CM_ "IMPORT _honda_common.dbc";
CM_ "IMPORT _bosch_2018.dbc";
CM_ "IMPORT _bosch_adas_2018.dbc";
CM_ "IMPORT _bosch_standstill.dbc";
CM_ "IMPORT _steering_sensors_b.dbc";

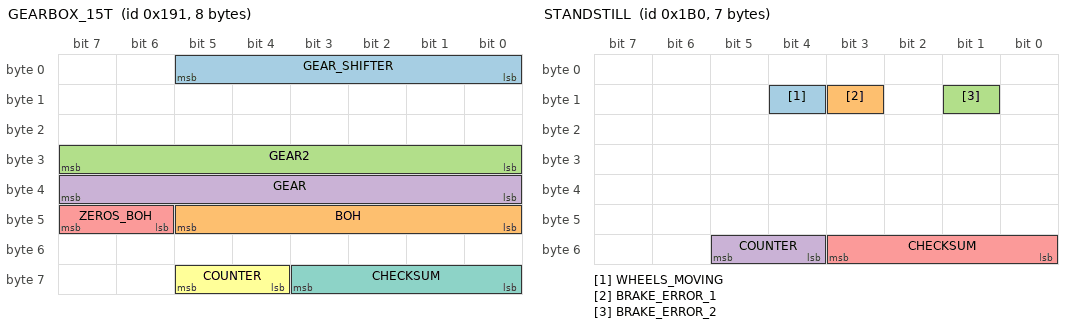
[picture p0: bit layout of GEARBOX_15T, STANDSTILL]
BO_ 401 GEARBOX_15T: 8 PCM
 SG_ GEAR_SHIFTER : 5|6@0+ (1,0) [0|63] "" EON
 SG_ BOH : 45|6@0+ (1,0) [0|63] "" XXX
 SG_ GEAR2 : 31|8@0+ (1,0) [0|1] "" XXX
 SG_ GEAR : 39|8@0+ (1,0) [0|255] "" XXX
 SG_ ZEROS_BOH : 47|2@0+ (1,0) [0|3] "" XXX
 SG_ COUNTER : 61|2@0+ (1,0) [0|3] "" EON
 SG_ CHECKSUM : 59|4@0+ (1,0) [0|15] "" EON

BO_ 432 STANDSTILL: 7 VSA
 SG_ WHEELS_MOVING : 12|1@0+ (1,0) [0|1] "" EON
 SG_ BRAKE_ERROR_1 : 11|1@0+ (1,0) [0|1] "" EON
 SG_ BRAKE_ERROR_2 : 9|1@0+ (1,0) [0|1] "" EON
 SG_ COUNTER : 53|2@0+ (1,0) [0|3] "" EON
 SG_ CHECKSUM : 51|4@0+ (1,0) [0|15] "" EON

VAL_ 401 GEAR_SHIFTER 32 "L" 16 "S" 8 "D" 4 "N" 2 "R" 1 "P";
VAL_ 401 GEAR 7 "L" 10 "S" 4 "D" 3 "N" 2 "R" 1 "P";
